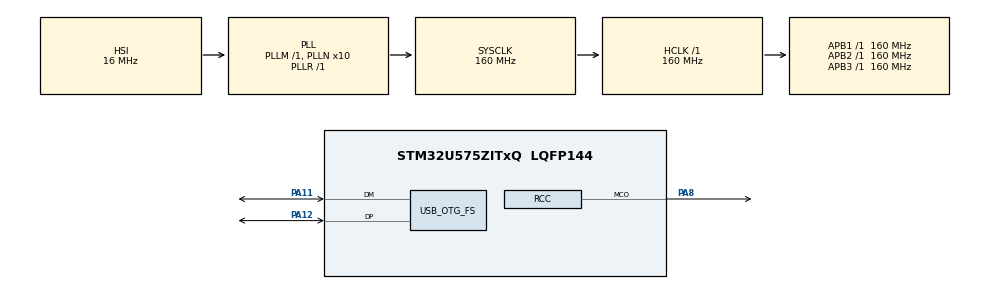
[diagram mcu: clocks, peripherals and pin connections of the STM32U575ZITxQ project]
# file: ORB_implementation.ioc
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CORTEX_M33_NS.userName=CORTEX_M33
ICACHE.Region=_NULL
Mcu.Family=STM32U5
Mcu.Name=STM32U575ZITxQ
Mcu.Package=LQFP144
NUCLEO-U575ZI-Q.BUTTON=1
NUCLEO-U575ZI-Q.LD1=true
NUCLEO-U575ZI-Q.LD2=true
NUCLEO-U575ZI-Q.LD3=true
NUCLEO-U575ZI-Q.VCP=true
NVIC.EXTI13_IRQn=true\:0\:0\:false\:false\:true\:false\:true\:true
NVIC.PriorityGroup=NVIC_PRIORITYGROUP_3
NVIC.TIM17_IRQn=true\:7\:0\:false\:false\:true\:false\:true\:true
NVIC.TimeBase=TIM17_IRQn
NVIC.TimeBaseIP=TIM17
PA10.Signal=USART1_RX
PA11.Mode=Device_Only
PA11.Signal=USB_OTG_FS_DM
PA12.Mode=Device_Only
PA12.Signal=USB_OTG_FS_DP
PA13\ (JTMS/SWDIO).Mode=Serial_Wire
PA13\ (JTMS/SWDIO).Signal=DEBUG_JTMS-SWDIO
PA14\ (JTCK/SWCLK).Mode=Serial_Wire
PA14\ (JTCK/SWCLK).Signal=DEBUG_JTCK-SWCLK
PA8.Mode=Clock-out
PA8.Signal=RCC_MCO
PA9.Signal=USART1_TX
PB3\ (JTDO/TRACESWO).Signal=DEBUG_JTDO-SWO
PC14-OSC32_IN\ (PC14).Signal=RCC_OSC32_IN
PC15-OSC32_OUT\ (PC15).Signal=RCC_OSC32_OUT
PWR.PowerMode=PWR_SMPS_SUPPLY
ProjectManager.HeapSize=0x200
ProjectManager.StackSize=0x400
ProjectManager.TargetToolchain=STM32CubeIDE
RCC.ADCFreq_Value=16000000
RCC.AHBFreq_Value=160000000
RCC.APB1Freq_Value=160000000
RCC.APB1TimFreq_Value=160000000
RCC.APB2Freq_Value=160000000
RCC.APB2TimFreq_Value=160000000
RCC.APB3Freq_Value=160000000
RCC.CortexFreq_Value=160000000
RCC.DACCLockSelectionVirtual=RCC_DAC1CLKSOURCE_LSI
RCC.EPOD_VALUE=16000000
RCC.HCLKFreq_Value=160000000
RCC.HSE_VALUE=16000000
RCC.HSI48_VALUE=48000000
RCC.HSI_VALUE=16000000
RCC.LSE_VALUE=32768
RCC.LSIDIV_VALUE=32000
RCC.MSIClockRange=RCC_MSIRANGE_0
RCC.MSI_VALUE=48000000
RCC.PLL1MBOOST=RCC_PLLMBOOST_DIV1
RCC.PLL1R=1
RCC.PLL2FRACN=0
RCC.PLL3FRACN=0
RCC.PLLFRACN=0
RCC.PLLN=10
RCC.PLLSourceVirtual=RCC_PLLSOURCE_HSI
RCC.PWR_Regulator_Voltage_Scale=PWR_REGULATOR_VOLTAGE_SCALE1
RCC.SYSCLKFreq_VALUE=160000000
RCC.SYSCLKSource=RCC_SYSCLKSOURCE_PLLCLK
RCC.USBFreq_Value=48000000
RCC.VCOOutputFreq_Value=160000000
USB_OTG_FS.VirtualMode=Device_Only
VP_CORDIC_VS_CORDIC.Mode=CORDIC_Activate
VP_CRC_VS_CRC.Mode=CRC_Activate
VP_DCACHE1_VS_DCACHE.Mode=DCACHE_Activate
VP_FLASH_SIG_Activate_FlashIP.Mode=Activate_FlashIP
VP_FMAC_VS_FMAC.Mode=FMAC_Activate
VP_ICACHE_VS_ENABLE_ICACHE_MEMORY.Mode=Memoryregions
VP_ICACHE_VS_ICACHE.Mode=DefaultMode
VP_LPBAMQUEUE_VS_QUEUE.Mode=QUEUEMODE
VP_LPBAM_VS_SIG1.Mode=SmartRun
VP_LPBAM_VS_SIG4.Mode=LPDMA1
VP_MEMORYMAP_VS_MEMORYMAP.Mode=CurAppReg
VP_NUCLEO-U575ZI-Q_VS_BSP_COMMON.Mode=COMMON
VP_PWR_VS_DBSignals.Mode=DisableDeadBatterySignals
VP_PWR_VS_LPOM.Mode=PowerOptimisation
VP_PWR_VS_SECSignals.Mode=Security/Privilege
VP_SYS_VS_tim17.Mode=TIM17
board=NUCLEO-U575ZI-Q

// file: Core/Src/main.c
/* USER CODE BEGIN Header */
/**
  ******************************************************************************
  * @file           : main.c
  * @brief          : Main program body
  ******************************************************************************
  * @attention
  *
  * Copyright (c) 2026 STMicroelectronics.
  * All rights reserved.
  *
  * This software is licensed under terms that can be found in the LICENSE file
  * in the root directory of this software component.
  * If no LICENSE file comes with this software, it is provided AS-IS.
  *
  ******************************************************************************
  */
/* USER CODE END Header */
#include "main.h"
#include "cordic.h"
#include "crc.h"
#include "dcache.h"
#include "flash.h"
#include "fmac.h"
#include "icache.h"
#include "usb_otg.h"
#include "gpio.h"

/* USER CODE BEGIN Includes */

#include "test_image.h"
#include "ORB.h"
#include "FAST.h"
#include <string.h>
#include "Benchmarking.h"
#include "Benchmarking_map.h"
#include "config.h"
#include "common_includes.h"
#include "output.h"
#include "profiling_config.h"

/* USER CODE END Includes */

/* USER CODE BEGIN PM */
#define DEBUG_VAR(x) (void)(x)
//#define UNUSED __attribute__((unused))
/* USER CODE END PM */

COM_InitTypeDef BspCOMInit;

void SystemClock_Config(void);
static void SystemPower_Config(void);

/* USER CODE BEGIN 0 */

// Makes it so printf gets to the debugger terminal
__attribute__((used))	int _write(int fd, char *ptr, int len) {
		(void)fd;
	    for (int i = 0; i < len; i++) {
	        while (ITM->PORT[0].u32 == 0);  // wait until ready
	        ITM->PORT[0].u8 = (uint8_t)ptr[i];
	    }
	    return (len);
	}

// In main.c, add these two functions
void stack_paint(void) {
	extern uint32_t _estack;
	extern uint32_t _Min_Stack_Size;
	uint32_t stack_bottom = (uint32_t)&_estack - (uint32_t)&_Min_Stack_Size;
	uint32_t *p = (uint32_t*)stack_bottom;
	while (p < (uint32_t*)__get_MSP())
		*p++ = 0xDEADBEEF;
}

uint32_t stack_usage(void) {
	extern uint32_t _estack;
	extern uint32_t _Min_Stack_Size;
	uint32_t stack_bottom = (uint32_t)&_estack - (uint32_t)&_Min_Stack_Size;
	uint32_t *p = (uint32_t*)stack_bottom;
	while (*p == 0xDEADBEEF) p++;
	return (uint32_t)&_estack - (uint32_t)p;
}

/* USER CODE END 0 */

int main(void)
{

  /* USER CODE BEGIN 1 */
	stack_paint();

	//CoreDebug->DEMCR |= CoreDebug_DEMCR_TRCENA_Msk;
	//DWT->CYCCNT = 0;
	//DWT->CTRL |= DWT_CTRL_CYCCNTENA_Msk;

	profiling_init();

	// Trying to get the image into ram
	static uint8_t image_ram[IMAGE_WIDTH * IMAGE_HEIGTH];
	memcpy(image_ram, test_image, sizeof(image_ram));

	static const int num_pixels = IMAGE_HEIGTH * IMAGE_WIDTH;
	// Kitty dataset has 1241 x 376
	static const int32_t kitti_num_pixels = 1241 * 376;

  /* USER CODE END 1 */

  /* MCU Configuration--------------------------------------------------------*/

  /* Reset of all peripherals, Initializes the Flash interface and the Systick. */
  HAL_Init();

  /* USER CODE BEGIN Init */

  volatile uint32_t clock1 = HAL_RCC_GetHCLKFreq();

   ORB_init(image_ram);
  /* USER CODE END Init */

  /* Configure the System Power */
  SystemPower_Config();

  /* Configure the system clock */
  SystemClock_Config();

  /* Initialize all configured peripherals */
  MX_GPIO_Init();
  MX_CORDIC_Init();
  MX_CRC_Init();
  MX_DCACHE1_Init();
  MX_FLASH_Init();
  MX_FMAC_Init();
  MX_ICACHE_Init();
  MX_USB_OTG_FS_PCD_Init();
  /* USER CODE BEGIN 2 */
  // To update the system clock
  SystemCoreClockUpdate();

  /* USER CODE END 2 */

  /* Initialize leds */
  BSP_LED_Init(LED_GREEN);
  BSP_LED_Init(LED_BLUE);
  BSP_LED_Init(LED_RED);

  /* Initialize USER push-button, will be used to trigger an interrupt each time it's pressed.*/
  BSP_PB_Init(BUTTON_USER, BUTTON_MODE_EXTI);

  /* Initialize COM1 port (115200, 8 bits (7-bit data + 1 stop bit), no parity */
  BspCOMInit.BaudRate   = 115200;
  BspCOMInit.WordLength = COM_WORDLENGTH_8B;
  BspCOMInit.StopBits   = COM_STOPBITS_1;
  BspCOMInit.Parity     = COM_PARITY_NONE;
  BspCOMInit.HwFlowCtl  = COM_HWCONTROL_NONE;
  if (BSP_COM_Init(COM1, &BspCOMInit) != BSP_ERROR_NONE)
  {
    Error_Handler();
  }

  /* Infinite loop */
  /* USER CODE BEGIN WHILE */
  //HAL_StatusTypeDef osc_result = HAL_RCC_OscConfig(&RCC_OscInitStruct);
  //HAL_StatusTypeDef clk_result = HAL_RCC_ClockConfig(&RCC_ClkInitStruct, FLASH_LATENCY_4);
  //printf(osc_result);
  volatile uint32_t clock2 = HAL_RCC_GetHCLKFreq();

  while (1)
  {

    /* USER CODE END WHILE */

    /* USER CODE BEGIN 3 */
	  BSP_LED_Toggle(LED_GREEN);
	  HAL_Delay(LED_BLINK_WAIT);
	  BSP_LED_Toggle(LED_RED);
	  HAL_Delay(LED_BLINK_WAIT);

/*************************  ORB Calculations Start*******************************************/
	  DWT_start(idx_ORB_total);

	  ORB_extract_and_match();

	  DWT_stop(idx_ORB_total);
	  DWT_process_data(idx_ORB_total);
	  DWT_convert_all_profiles_to_timed();
	  DWT_Profile_t *ORB_profile = DWT_get(idx_ORB_total);
	  DWT_timed_pair_t *Orb_profile_timed =DWT_get_timed(idx_ORB_total);

#if ORB_PROFILING
	  DWT_timed_pair_t *FAST_timed =DWT_get_timed(idx_FAST_total);
	  DWT_timed_pair_t *HARRIS_timed =DWT_get_timed(idx_HARRIS_total);
	  DWT_timed_pair_t *Centroid_timed =DWT_get_timed(idx_Centroid_total);
	  DWT_timed_pair_t *rBRIEF_timed =DWT_get_timed(idx_rBRIEF_total);
	  DWT_timed_pair_t *ORB_all_profiles_timed =DWT_get_timed_registry();

	  DEBUG_VAR(ORB_all_profiles_timed);
	  DEBUG_VAR(FAST_timed);
	  DEBUG_VAR(HARRIS_timed);
	  DEBUG_VAR(Centroid_timed);
	  DEBUG_VAR(rBRIEF_timed);
#endif
	  double us_per_pixel = (int)ORB_profile->avg/num_pixels;
	  us_per_pixel = us_per_pixel/(SystemCoreClock / 1000000.0);
	  double kitti_time_us = us_per_pixel*kitti_num_pixels;
	  const char feature_msg[] = "First try at Making a merged Optimized code for FAST and Harris";
	  const char performance_msg[] = "";
	  output_commit_message(feature_msg,performance_msg );

	  uint32_t used = stack_usage();
	  DWT_aggregate_reset_all();
	  uint32_t num_of_high_speed_rejections_total = num_of_high_speed_rejections();
	  volatile uint32_t num_of_conc_rejections = num_of_concecutive_rejections();
	  DEBUG_VAR(idx_ORB_total);

	  DEBUG_VAR(ORB_profile);
	  DEBUG_VAR(Orb_profile_timed);

	  DEBUG_VAR(num_pixels);
	  DEBUG_VAR(kitti_num_pixels);
	  DEBUG_VAR(kitti_time_us);

   	  DEBUG_VAR(clock1);
	  DEBUG_VAR(clock2);
	  DEBUG_VAR(used);
	  //DEBUG_VAR(val);
	  DEBUG_VAR(Orb_profile_timed);
	  DEBUG_VAR(ORB_profile);
	  DEBUG_VAR(num_of_high_speed_rejections_total);
	  DEBUG_VAR(num_of_conc_rejections);

	  /*
	  uint32_t microseconds = cycles / (SystemCoreClock / 1000000U);
	  volatile double milliseconds = (double)microseconds /1000.0;

	  ORB_feature_point_t first_one = feature_points[0];
	  volatile uint16_t num_of_feature_points = FAST_get_feature_count();
	  volatile double microseconds_per_pixel = (double)microseconds/num_pixels;
	  volatile double KITII_time_Extrapolated = (1241*376) * microseconds_per_pixel/ 1000.0;

	  DEBUG_VAR(KITII_time_Extrapolated);
	  DEBUG_VAR(num_of_feature_points);
	  DEBUG_VAR(first_one);
	  DEBUG_VAR(milliseconds);
	  */

  }
  /* USER CODE END 3 */
}

void SystemClock_Config(void)
{
  RCC_OscInitTypeDef RCC_OscInitStruct = {0};
  RCC_ClkInitTypeDef RCC_ClkInitStruct = {0};

  /** Configure the main internal regulator output voltage
  */
  if (HAL_PWREx_ControlVoltageScaling(PWR_REGULATOR_VOLTAGE_SCALE1) != HAL_OK)
  {
    Error_Handler();
  }

  /** Initializes the CPU, AHB and APB buses clocks
  */
  RCC_OscInitStruct.OscillatorType = RCC_OSCILLATORTYPE_HSI48|RCC_OSCILLATORTYPE_HSI;
  RCC_OscInitStruct.HSIState = RCC_HSI_ON;
  RCC_OscInitStruct.HSI48State = RCC_HSI48_ON;
  RCC_OscInitStruct.HSICalibrationValue = RCC_HSICALIBRATION_DEFAULT;
  RCC_OscInitStruct.PLL.PLLState = RCC_PLL_ON;
  RCC_OscInitStruct.PLL.PLLSource = RCC_PLLSOURCE_HSI;
  RCC_OscInitStruct.PLL.PLLMBOOST = RCC_PLLMBOOST_DIV1;
  RCC_OscInitStruct.PLL.PLLM = 1;
  RCC_OscInitStruct.PLL.PLLN = 10;
  RCC_OscInitStruct.PLL.PLLP = 2;
  RCC_OscInitStruct.PLL.PLLQ = 2;
  RCC_OscInitStruct.PLL.PLLR = 1;
  RCC_OscInitStruct.PLL.PLLRGE = RCC_PLLVCIRANGE_1;
  RCC_OscInitStruct.PLL.PLLFRACN = 0;
  if (HAL_RCC_OscConfig(&RCC_OscInitStruct) != HAL_OK)
  {
    Error_Handler();
  }

  /** Initializes the CPU, AHB and APB buses clocks
  */
  RCC_ClkInitStruct.ClockType = RCC_CLOCKTYPE_HCLK|RCC_CLOCKTYPE_SYSCLK
                              |RCC_CLOCKTYPE_PCLK1|RCC_CLOCKTYPE_PCLK2
                              |RCC_CLOCKTYPE_PCLK3;
  RCC_ClkInitStruct.SYSCLKSource = RCC_SYSCLKSOURCE_PLLCLK;
  RCC_ClkInitStruct.AHBCLKDivider = RCC_SYSCLK_DIV1;
  RCC_ClkInitStruct.APB1CLKDivider = RCC_HCLK_DIV1;
  RCC_ClkInitStruct.APB2CLKDivider = RCC_HCLK_DIV1;
  RCC_ClkInitStruct.APB3CLKDivider = RCC_HCLK_DIV1;

  if (HAL_RCC_ClockConfig(&RCC_ClkInitStruct, FLASH_LATENCY_4) != HAL_OK)
  {
    Error_Handler();
  }

  /** MCO configuration
  */
  HAL_RCC_MCOConfig(RCC_MCO1, RCC_MCO1SOURCE_SYSCLK, RCC_MCODIV_1);
}

/**
  * @brief Power Configuration
  * @retval None
  */
static void SystemPower_Config(void)
{

  /*
   * Disable the internal Pull-Up in Dead Battery pins of UCPD peripheral
   */
  HAL_PWREx_DisableUCPDDeadBattery();

  /*
   * Switch to SMPS regulator instead of LDO
   */
  if (HAL_PWREx_ConfigSupply(PWR_SMPS_SUPPLY) != HAL_OK)
  {
    Error_Handler();
  }
}

void HAL_TIM_PeriodElapsedCallback(TIM_HandleTypeDef *htim)
{
  if (htim->Instance == TIM17)
  {
    HAL_IncTick();
  }
}

void Error_Handler(void)
{
  __disable_irq();
  while (1)
  {
  }
}
